AUTOSAR XML (schema 4-3-0)
package /Impl_SWC_HALOUT_ARPkg
  swc implementation Impl_SWC_HALOUT_type: programming-language=C, sw-version=1.0.0, vendor-id=0, behavior=SWC_HALOUT_type_IB
    code-descriptors:
      code SRC: artifact-descriptors=autosar-engineering-object={short-label=EngObject, category=SWSRC}
    resource consumption ResourceConsumption
      memory section MEM_SWC_HALOUT_CAL: size=0, sw-addrmethod=CAL, symbol=CAL
      memory section MEM_SWC_HALOUT_CODE: size=0, sw-addrmethod=CODE, symbol=CODE
package /SWC_HALOUT_ARPkg
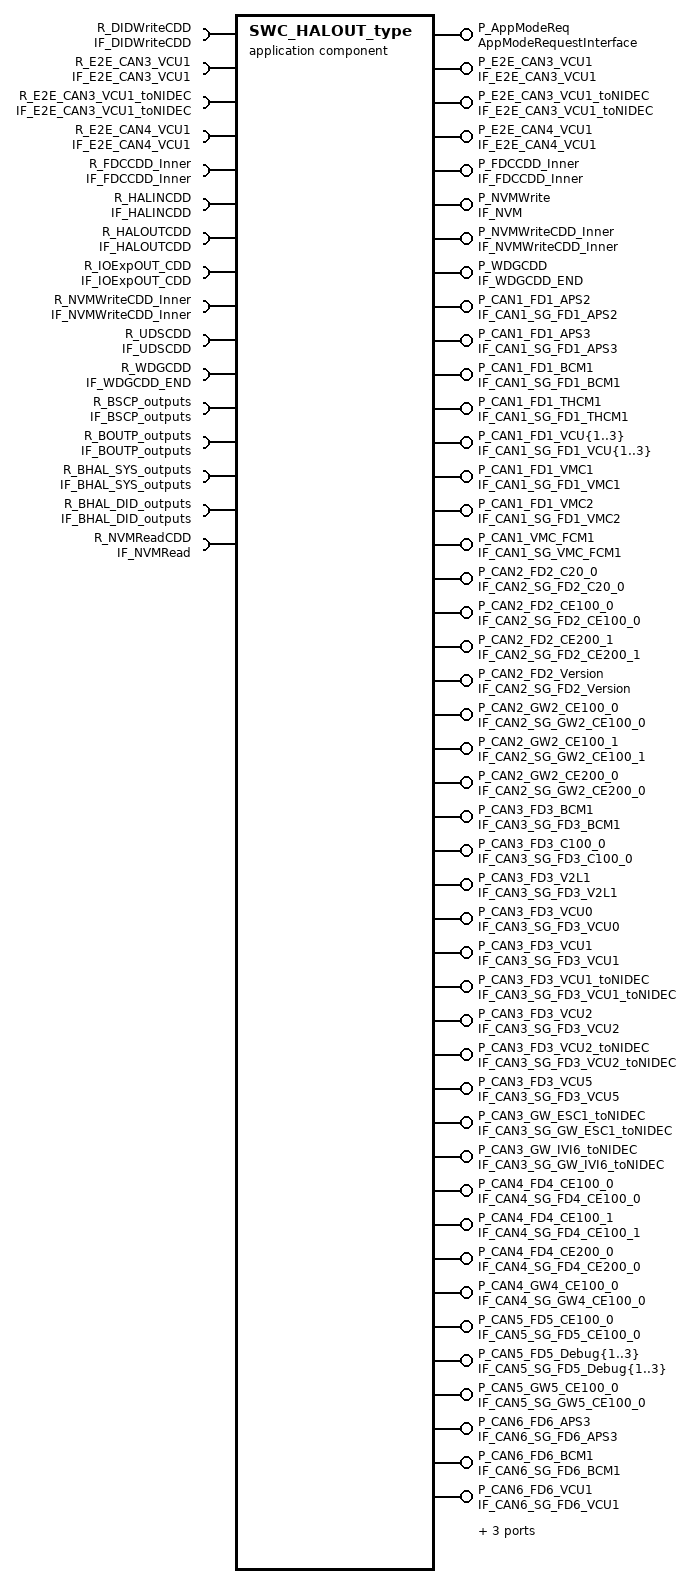
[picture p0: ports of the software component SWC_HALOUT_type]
  application sw component type SWC_HALOUT_type
    51 x provide port:
      P_AppModeReq: provided-interface=AppModeRequestInterface
      P_E2E_CAN3_VCU1: provided-interface=IF_E2E_CAN3_VCU1
      P_E2E_CAN3_VCU1_toNIDEC: provided-interface=IF_E2E_CAN3_VCU1_toNIDEC
      P_E2E_CAN4_VCU1: provided-interface=IF_E2E_CAN4_VCU1
      P_FDCCDD_Inner: provided-interface=IF_FDCCDD_Inner
      P_NVMWrite: nv-provide-com-spec{ram-block-init-value=ValueSpecification_:1024 x 0, rom-block-init-value=ValueSpecification_:1024 x 0, variable=NV_FVTDataArray}, provided-interface=IF_NVM
      P_NVMWriteCDD_Inner: provided-interface=IF_NVMWriteCDD_Inner
      P_WDGCDD: provided-interface=IF_WDGCDD_END
      P_CAN1_FD1_APS2: provided-interface=IF_CAN1_SG_FD1_APS2
      P_CAN1_FD1_APS3: provided-interface=IF_CAN1_SG_FD1_APS3
      P_CAN1_FD1_BCM1: provided-interface=IF_CAN1_SG_FD1_BCM1
      P_CAN1_FD1_THCM1: provided-interface=IF_CAN1_SG_FD1_THCM1
      P_CAN1_FD1_VCU{1..3}: provided-interface=IF_CAN1_SG_FD1_VCU{1..3}
      P_CAN1_FD1_VMC1: provided-interface=IF_CAN1_SG_FD1_VMC1
      P_CAN1_FD1_VMC2: provided-interface=IF_CAN1_SG_FD1_VMC2
      P_CAN1_VMC_FCM1: provided-interface=IF_CAN1_SG_VMC_FCM1
      P_CAN2_FD2_C20_0: provided-interface=IF_CAN2_SG_FD2_C20_0
      P_CAN2_FD2_CE100_0: provided-interface=IF_CAN2_SG_FD2_CE100_0
      P_CAN2_FD2_CE200_1: provided-interface=IF_CAN2_SG_FD2_CE200_1
      P_CAN2_FD2_Version: provided-interface=IF_CAN2_SG_FD2_Version
      P_CAN2_GW2_CE100_0: provided-interface=IF_CAN2_SG_GW2_CE100_0
      P_CAN2_GW2_CE100_1: provided-interface=IF_CAN2_SG_GW2_CE100_1
      P_CAN2_GW2_CE200_0: provided-interface=IF_CAN2_SG_GW2_CE200_0
      P_CAN3_FD3_BCM1: provided-interface=IF_CAN3_SG_FD3_BCM1
      P_CAN3_FD3_C100_0: provided-interface=IF_CAN3_SG_FD3_C100_0
      P_CAN3_FD3_V2L1: provided-interface=IF_CAN3_SG_FD3_V2L1
      P_CAN3_FD3_VCU0: provided-interface=IF_CAN3_SG_FD3_VCU0
      P_CAN3_FD3_VCU1: provided-interface=IF_CAN3_SG_FD3_VCU1
      P_CAN3_FD3_VCU1_toNIDEC: provided-interface=IF_CAN3_SG_FD3_VCU1_toNIDEC
      P_CAN3_FD3_VCU2: provided-interface=IF_CAN3_SG_FD3_VCU2
      P_CAN3_FD3_VCU2_toNIDEC: provided-interface=IF_CAN3_SG_FD3_VCU2_toNIDEC
      P_CAN3_FD3_VCU5: provided-interface=IF_CAN3_SG_FD3_VCU5
      P_CAN3_GW_ESC1_toNIDEC: provided-interface=IF_CAN3_SG_GW_ESC1_toNIDEC
      P_CAN3_GW_IVI6_toNIDEC: provided-interface=IF_CAN3_SG_GW_IVI6_toNIDEC
      P_CAN4_FD4_CE100_0: provided-interface=IF_CAN4_SG_FD4_CE100_0
      P_CAN4_FD4_CE100_1: provided-interface=IF_CAN4_SG_FD4_CE100_1
      P_CAN4_FD4_CE200_0: provided-interface=IF_CAN4_SG_FD4_CE200_0
      P_CAN4_GW4_CE100_0: provided-interface=IF_CAN4_SG_GW4_CE100_0
      P_CAN5_FD5_CE100_0: provided-interface=IF_CAN5_SG_FD5_CE100_0
      P_CAN5_FD5_Debug{1..3}: provided-interface=IF_CAN5_SG_FD5_Debug{1..3}
      P_CAN5_GW5_CE100_0: provided-interface=IF_CAN5_SG_GW5_CE100_0
      P_CAN6_FD6_APS3: provided-interface=IF_CAN6_SG_FD6_APS3
      P_CAN6_FD6_BCM1: provided-interface=IF_CAN6_SG_FD6_BCM1
      P_CAN6_FD6_VCU1: provided-interface=IF_CAN6_SG_FD6_VCU1
      P_CAN6_FD6_VCU2: provided-interface=IF_CAN6_SG_FD6_VCU2
      P_CAN6_FD6_VMC1: provided-interface=IF_CAN6_SG_FD6_VMC1
      P_CAN6_GW6_CE100_0: provided-interface=IF_CAN6_SG_GW6_CE100_0
    16 x require port:
      R_DIDWriteCDD: required-interface=IF_DIDWriteCDD
      R_E2E_CAN3_VCU1: required-interface=IF_E2E_CAN3_VCU1
      R_E2E_CAN3_VCU1_toNIDEC: required-interface=IF_E2E_CAN3_VCU1_toNIDEC
      R_E2E_CAN4_VCU1: required-interface=IF_E2E_CAN4_VCU1
      R_FDCCDD_Inner: required-interface=IF_FDCCDD_Inner
      R_HALINCDD: required-interface=IF_HALINCDD
      R_HALOUTCDD: required-interface=IF_HALOUTCDD
      R_IOExpOUT_CDD: required-interface=IF_IOExpOUT_CDD
      R_NVMWriteCDD_Inner: required-interface=IF_NVMWriteCDD_Inner
      R_UDSCDD: required-interface=IF_UDSCDD
      R_WDGCDD: required-interface=IF_WDGCDD_END
      R_BSCP_outputs: required-interface=IF_BSCP_outputs
      R_BOUTP_outputs: required-interface=IF_BOUTP_outputs
      R_BHAL_SYS_outputs: required-interface=IF_BHAL_SYS_outputs
      R_BHAL_DID_outputs: required-interface=IF_BHAL_DID_outputs
      R_NVMReadCDD: required-interface=IF_NVMRead
    behavior SWC_HALOUT_type_IB: data-type-mapping=AppModeTypeMap, handle-termination-and-restart=NO-SUPPORT
      8 x timing event:
        TE_HALOUT_100ms: start-on-event=run_SWC_HALOUT_Tx_100ms, period=0.1
        TE_HALOUT_1000ms: start-on-event=run_SWC_HALOUT_Tx_1000ms, period=1
        TE_HALOUT_20ms: start-on-event=run_SWC_HALOUT_Tx_20ms, period=0.02
        TE_HALOUT_500ms: start-on-event=run_SWC_HALOUT_Tx_500ms, period=0.5
        TE_HALOUT_5000ms: start-on-event=run_SWC_HALOUT_Tx_5000ms, period=5
        TE_HALOUT_10ms: start-on-event=run_SWC_HALOUT_Tx_10ms, period=0.01
        TE_HALOUT_5ms: start-on-event=run_SWC_HALOUT_Tx_5ms, period=0.005
        TE_UDS_10ms: start-on-event=run_SWC_HALOUT_UDS_10ms, period=0.01
      6 x operation invoked event:
        oie_P_WDGCDD_CSOP_Call_WDG_AppEnd: start-on-event=run_SWC_HALOUT_AppCallWDG_End, operation=P_WDGCDD.CSOP_Call_WDG_AppEnd
        oie_P_E2E_CAN3_VCU1_CSOP_Write_CAN3_VCU1: start-on-event=run_SWC_HALOUT_E2E_Write_CAN3VCU1, operation=P_E2E_CAN3_VCU1.CSOP_Write_CAN3_VCU1
        oie_P_E2E_CAN3_VCU1_CSOP_Write_CAN3_VCU1_toNIDEC: start-on-event=run_SWC_HALOUT_E2E_Write_CAN3VCU1_toNIDEC, operation=P_E2E_CAN3_VCU1_toNIDEC.CSOP_Write_CAN3_VCU1_toNIDEC
        oie_P_E2E_CAN4_VCU1_CSOP_Write_CAN4_VCU1: start-on-event=run_SWC_HALOUT_E2E_Write_CAN4VCU1, operation=P_E2E_CAN4_VCU1.CSOP_Write_CAN4_VCU1
        oie_P_FDCCDD_Inner_CSOP_FDC_AppCallSleep: start-on-event=run_SWC_HALOUT_AppCallSleep, operation=P_FDCCDD_Inner.CSOP_FDC_AppCallSleep
        oie_P_NVMWriteCDD_Inner_NVM_WriteOperation: start-on-event=run_SWC_HALOUT_NvmWrite, operation=P_NVMWriteCDD_Inner.NVM_WriteOperation
      explicit-inter-runnable-variables:
        25 x data:
          IRV_ms10_CAN1_SG_FD1_APS3: type=DT_CAN1_SG_FD1_APS3
          IRV_ms10_CAN1_SG_FD1_VCU2: type=DT_CAN1_SG_FD1_VCU2
          IRV_ms10_CAN1_SG_FD1_VCU3: type=DT_CAN1_SG_FD1_VCU3
          IRV_ms10_CAN1_SG_VMC_FCM1: type=DT_CAN1_SG_VMC_FCM1
          IRV_ms10_CAN3_SG_FD3_VCU0: type=DT_CAN3_SG_FD3_VCU0
          IRV_ms10_CAN3_SG_FD3_VCU2: type=DT_CAN3_SG_FD3_VCU2
          IRV_ms10_CAN3_SG_FD3_VCU2_toNIDEC: type=DT_CAN3_SG_FD3_VCU2_toNIDEC
          IRV_ms10_CAN3_SG_FD3_VCU5: type=DT_CAN3_SG_FD3_VCU5
          IRV_ms10_CAN3_SG_GW_ESC1_toNIDEC: type=DT_CAN3_SG_GW_ESC1_toNIDEC
          IRV_ms10_CAN5_SG_FD5_Debug3: type=DT_CAN5_SG_FD5_Debug3
          IRV_ms10_CAN6_SG_FD6_APS3: type=DT_CAN6_SG_FD6_APS3
          IRV_ms10_CAN6_SG_FD6_VCU2: type=DT_CAN6_SG_FD6_VCU2
          IRV_ms100_CAN1_SG_FD1_THCM1: type=DT_CAN1_SG_FD1_THCM1
          IRV_ms100_CAN2_SG_GW2_CE100_1: type=DT_CAN2_SG_GW2_CE100_1
          IRV_ms100_CAN3_SG_FD3_C100_0: type=DT_CAN3_SG_FD3_C100_0
          IRV_ms100_CAN5_SG_GW5_CE100_0: type=DT_CAN5_SG_GW5_CE100_0
          IRV_ms1000_CAN3_SG_GW_IVI6_toNIDEC: type=DT_CAN3_SG_GW_IVI6_toNIDEC
          IRV_ms20_CAN1_SG_FD1_APS2: type=DT_CAN1_SG_FD1_APS2
          IRV_ms20_CAN2_SG_FD2_C20_0: type=DT_CAN2_SG_FD2_C20_0
          IRV_ms500_CAN1_SG_FD1_VMC2: type=DT_CAN1_SG_FD1_VMC2
          IRV_ms5000_CAN2_SG_FD2_Version: type=DT_CAN2_SG_FD2_Version
          IRV_E2E_CAN3_SG_FD3_VCU1: type=DT_CAN3_SG_FD3_VCU1
          IRV_E2E_CAN3_SG_FD3_VCU1_toNIDEC: type=DT_CAN3_SG_FD3_VCU1_toNIDEC
          IRV_E2E_CAN4_SG_FD4_CE100_0: type=DT_CAN4_SG_FD4_CE100_0
          IRV_u8Array1024_NvmWriteArray: type=u8_FVTNVMArray1024_type
      port-api-options:
        enable-take-address=false, indirect-api=false, port=P_FDCCDD_Inner
        enable-take-address=false, indirect-api=false, port=P_NVMWriteCDD_Inner
        enable-take-address=false, indirect-api=false, port=P_E2E_CAN3_VCU1
        enable-take-address=false, indirect-api=false, port=P_E2E_CAN3_VCU1_toNIDEC
        enable-take-address=false, indirect-api=false, port=P_E2E_CAN4_VCU1
        enable-take-address=false, indirect-api=false, port=P_WDGCDD
      14 x runnable:
        run_SWC_HALOUT_Tx_100ms
          data-send-points:
            4 x access:
              dsp_CAN1_SG_FD1_THCM1: accessed-variable=P_CAN1_FD1_THCM1.CAN1_SG_FD1_THCM1
              dsp_CAN2_SG_GW2_CE100_1: accessed-variable=P_CAN2_GW2_CE100_1.CAN2_SG_GW2_CE100_1
              dsp_CAN3_SG_FD3_C100_0: accessed-variable=P_CAN3_FD3_C100_0.CAN3_SG_FD3_C100_0
              dsp_CAN5_SG_GW5_CE100_0: accessed-variable=P_CAN5_GW5_CE100_0.CAN5_SG_GW5_CE100_0
          read-local-variables:
            4 x access:
              IRV_ms100_CAN1_SG_FD1_THCM1: accessed-variable=IRV_ms100_CAN1_SG_FD1_THCM1
              IRV_ms100_CAN2_SG_GW2_CE100_1: accessed-variable=IRV_ms100_CAN2_SG_GW2_CE100_1
              IRV_ms100_CAN3_SG_FD3_C100_0: accessed-variable=IRV_ms100_CAN3_SG_FD3_C100_0
              IRV_ms100_CAN5_SG_GW5_CE100_0: accessed-variable=IRV_ms100_CAN5_SG_GW5_CE100_0
        run_SWC_HALOUT_Tx_1000ms
          data-send-points:
            access dsp_CAN3_SG_GW_IVI6_toNIDEC: accessed-variable=P_CAN3_GW_IVI6_toNIDEC.CAN3_SG_GW_IVI6_toNIDEC
          read-local-variables:
            access IRV_ms1000_CAN3_SG_GW_IVI6_toNIDEC: accessed-variable=IRV_ms1000_CAN3_SG_GW_IVI6_toNIDEC
        run_SWC_HALOUT_Tx_20ms
          data-send-points:
            access dsp_CAN1_SG_FD1_APS2: accessed-variable=P_CAN1_FD1_APS2.CAN1_SG_FD1_APS2
            access dsp_CAN2_SG_FD2_C20_0: accessed-variable=P_CAN2_FD2_C20_0.CAN2_SG_FD2_C20_0
          read-local-variables:
            access IRV_ms20_CAN1_SG_FD1_APS2: accessed-variable=IRV_ms20_CAN1_SG_FD1_APS2
            access IRV_ms20_CAN2_SG_FD2_C20_0: accessed-variable=IRV_ms20_CAN2_SG_FD2_C20_0
        run_SWC_HALOUT_Tx_500ms
          data-send-points:
            access dsp_CAN1_SG_FD1_VMC2: accessed-variable=P_CAN1_FD1_VMC2.CAN1_SG_FD1_VMC2
          read-local-variables:
            access IRV_ms500_CAN1_SG_FD1_VMC2: accessed-variable=IRV_ms500_CAN1_SG_FD1_VMC2
        run_SWC_HALOUT_Tx_5000ms
          data-send-points:
            access dsp_CAN2_SG_FD2_Version: accessed-variable=P_CAN2_FD2_Version.CAN2_SG_FD2_Version
          read-local-variables:
            access IRV_ms5000_CAN2_SG_FD2_Version: accessed-variable=IRV_ms5000_CAN2_SG_FD2_Version
        run_SWC_HALOUT_AppCallSleep
          data-send-points:
            access dsp_requestedMode: accessed-variable=P_AppModeReq.requestedMode
        run_SWC_HALOUT_E2E_Write_CAN3VCU1
          data-send-points:
            access dsp_CAN3_SG_FD3_VCU1: accessed-variable=P_CAN3_FD3_VCU1.CAN3_SG_FD3_VCU1
          read-local-variables:
            access IRV_E2E_CAN3_SG_FD3_VCU1: accessed-variable=IRV_E2E_CAN3_SG_FD3_VCU1
        run_SWC_HALOUT_E2E_Write_CAN3VCU1_toNIDEC
          data-send-points:
            access dsp_CAN3_SG_FD3_VCU1_toNIDEC: accessed-variable=P_CAN3_FD3_VCU1_toNIDEC.CAN3_SG_FD3_VCU1_toNIDEC
          read-local-variables:
            access IRV_E2E_CAN3_SG_FD3_VCU1_toNIDEC: accessed-variable=IRV_E2E_CAN3_SG_FD3_VCU1_toNIDEC
        run_SWC_HALOUT_E2E_Write_CAN4VCU1
          data-send-points:
            access dsp_CAN4_SG_FD4_CE100_0: accessed-variable=P_CAN4_FD4_CE100_0.CAN4_SG_FD4_CE100_0
          read-local-variables:
            access IRV_E2E_CAN4_SG_FD4_CE100_0: accessed-variable=IRV_E2E_CAN4_SG_FD4_CE100_0
        run_SWC_HALOUT_NvmWrite
          data-send-points:
            access dsp_NV_FVTDataArray: accessed-variable=P_NVMWrite.NV_FVTDataArray
          read-local-variables:
            access IRV_u8Array1024_NvmWriteArray: accessed-variable=IRV_u8Array1024_NvmWriteArray
        run_SWC_HALOUT_Tx_5ms
          data-receive-point-by-arguments:
            5 x access:
              drparg_BSCP_outputs: accessed-variable=R_BSCP_outputs.BSCP_outputs
              drparg_BOUTP_outputs: accessed-variable=R_BOUTP_outputs.BOUTP_outputs
              drparg_BHAL_SYS_outputs: accessed-variable=R_BHAL_SYS_outputs.BHAL_SYS_outputs
              drparg_BHAL_DID_outputs: accessed-variable=R_BHAL_DID_outputs.BHAL_DID_outputs
              drparg_u8Array1024_NVMReadData: accessed-variable=R_NVMReadCDD.u8Array1024_NVMReadData
          data-send-points:
            19 x access:
              dsp_CAN1_SG_FD1_BCM1: accessed-variable=P_CAN1_FD1_BCM1.CAN1_SG_FD1_BCM1
              dsp_CAN1_SG_FD1_VCU1: accessed-variable=P_CAN1_FD1_VCU1.CAN1_SG_FD1_VCU1
              dsp_CAN1_SG_FD1_VMC1: accessed-variable=P_CAN1_FD1_VMC1.CAN1_SG_FD1_VMC1
              dsp_CAN2_SG_FD2_CE100_0: accessed-variable=P_CAN2_FD2_CE100_0.CAN2_SG_FD2_CE100_0
              dsp_CAN2_SG_FD2_CE200_1: accessed-variable=P_CAN2_FD2_CE200_1.CAN2_SG_FD2_CE200_1
              dsp_CAN2_SG_GW2_CE100_0: accessed-variable=P_CAN2_GW2_CE100_0.CAN2_SG_GW2_CE100_0
              dsp_CAN2_SG_GW2_CE200_0: accessed-variable=P_CAN2_GW2_CE200_0.CAN2_SG_GW2_CE200_0
              dsp_CAN3_SG_FD3_BCM1: accessed-variable=P_CAN3_FD3_BCM1.CAN3_SG_FD3_BCM1
              dsp_CAN3_SG_FD3_V2L1: accessed-variable=P_CAN3_FD3_V2L1.CAN3_SG_FD3_V2L1
              dsp_CAN4_SG_FD4_CE100_1: accessed-variable=P_CAN4_FD4_CE100_1.CAN4_SG_FD4_CE100_1
              dsp_CAN4_SG_FD4_CE200_0: accessed-variable=P_CAN4_FD4_CE200_0.CAN4_SG_FD4_CE200_0
              dsp_CAN4_SG_GW4_CE100_0: accessed-variable=P_CAN4_GW4_CE100_0.CAN4_SG_GW4_CE100_0
              dsp_CAN5_SG_FD5_CE100_0: accessed-variable=P_CAN5_FD5_CE100_0.CAN5_SG_FD5_CE100_0
              dsp_CAN5_SG_FD5_Debug1: accessed-variable=P_CAN5_FD5_Debug1.CAN5_SG_FD5_Debug1
              dsp_CAN5_SG_FD5_Debug2: accessed-variable=P_CAN5_FD5_Debug2.CAN5_SG_FD5_Debug2
              dsp_CAN6_SG_FD6_BCM1: accessed-variable=P_CAN6_FD6_BCM1.CAN6_SG_FD6_BCM1
              dsp_CAN6_SG_FD6_VCU1: accessed-variable=P_CAN6_FD6_VCU1.CAN6_SG_FD6_VCU1
              dsp_CAN6_SG_FD6_VMC1: accessed-variable=P_CAN6_FD6_VMC1.CAN6_SG_FD6_VMC1
              dsp_CAN6_SG_GW6_CE100_0: accessed-variable=P_CAN6_GW6_CE100_0.CAN6_SG_GW6_CE100_0
          72 x sync call, all with timeout=0.0:
            scp_CSOP_DdmRestartOperation: operation=R_UDSCDD.CSOP_DdmRestartOperationCycle
            scp_CSOP_FDC_AppCallSleep: operation=R_FDCCDD_Inner.CSOP_FDC_AppCallSleep
            scp_CSOP_IOExpSetVal: operation=R_IOExpOUT_CDD.CSOP_IOExpSetVal
            scp_CSOP_SetAcoreRebootCmdACK: operation=R_HALOUTCDD.CSOP_SetAcoreRebootCmdACK
            scp_CSOP_SetDTCStatus: operation=R_UDSCDD.CSOP_SetDTCStatus
            scp_CSOP_SetHazardIND: operation=R_HALOUTCDD.CSOP_SetHazardIND
            scp_CSOP_SetSysPwrStat: operation=R_HALOUTCDD.CSOP_SetSysPwrStat
            scp_CSOP_AppNmStateReq: operation=R_HALOUTCDD.CSOP_AppNmStateReq
            scp_CSOP_Call_WDG_AppEnd: operation=R_WDGCDD.CSOP_Call_WDG_AppEnd
            scp_CSOP_SleepRequest: operation=R_HALOUTCDD.CSOP_SleepRequest
            scp_CSOP_TPMSSensorIDRegSetResults: operation=R_HALOUTCDD.CSOP_TPMSSensorIDRegSetResults
            scp_CSOP_ResetPedalZeroPosDone: operation=R_HALOUTCDD.CSOP_ResetPedalZeroPosDone
            scp_CSOP_Write_CAN3_VCU1: operation=R_E2E_CAN3_VCU1.CSOP_Write_CAN3_VCU1
            scp_CSOP_Write_CAN3_VCU1_toNIDEC: operation=R_E2E_CAN3_VCU1_toNIDEC.CSOP_Write_CAN3_VCU1_toNIDEC
            scp_CSOP_Write_CAN4_VCU1: operation=R_E2E_CAN4_VCU1.CSOP_Write_CAN4_VCU1
            scp_CSOP_DIDSet_XWDMode: operation=R_DIDWriteCDD.CSOP_DIDSet_XWDMode
            scp_CSOP_DIDSet_DKCKey: operation=R_DIDWriteCDD.CSOP_DIDSet_DKCKey
            scp_CSOP_DIDSet_DynoMode: operation=R_DIDWriteCDD.CSOP_DIDSet_DynoMode
            scp_CSOP_DIDSet_APPPedalZP: operation=R_DIDWriteCDD.CSOP_DIDSet_APPPedalZP
            scp_CSOP_DIDSet_NVMPedalZP: operation=R_DIDWriteCDD.CSOP_DIDSet_NVMPedalZP
            scp_CSOP_DIDSet_TurnLampFRThreCurr: operation=R_DIDWriteCDD.CSOP_DIDSet_TurnLampFRThreCurr
            scp_CSOP_DIDSet_TurnLampRRThreCurr: operation=R_DIDWriteCDD.CSOP_DIDSet_TurnLampRRThreCurr
            scp_CSOP_DIDSet_TurnLampFLThreCurr: operation=R_DIDWriteCDD.CSOP_DIDSet_TurnLampFLThreCurr
            scp_CSOP_DIDSet_TurnLampRLThreCurr: operation=R_DIDWriteCDD.CSOP_DIDSet_TurnLampRLThreCurr
            scp_CSOP_DIDSet_FMHTimer: operation=R_DIDWriteCDD.CSOP_DIDSet_FMHTimer
            scp_CSOP_DIDSet_AutoLock: operation=R_DIDWriteCDD.CSOP_DIDSet_AutoLock
            scp_CSOP_DIDSet_DRLDis: operation=R_DIDWriteCDD.CSOP_DIDSet_DRLDis
            scp_CSOP_DIDSet_AutoWipHSpdEN: operation=R_DIDWriteCDD.CSOP_DIDSet_AutoWipHSpdEN
            scp_CSOP_DIDSet_WipRLSCmdHoldFilter: operation=R_DIDWriteCDD.CSOP_DIDSet_WipRLSCmdHoldFilter
            scp_CSOP_DIDSet_WipRLSCmdCutFilter: operation=R_DIDWriteCDD.CSOP_DIDSet_WipRLSCmdCutFilter
            scp_CSOP_DIDSet_LFSensorID: operation=R_DIDWriteCDD.CSOP_DIDSet_LFSensorID
            scp_CSOP_DIDSet_RFSensorID: operation=R_DIDWriteCDD.CSOP_DIDSet_RFSensorID
            scp_CSOP_DIDSet_LRSensorID: operation=R_DIDWriteCDD.CSOP_DIDSet_LRSensorID
            scp_CSOP_DIDSet_RRSensorID: operation=R_DIDWriteCDD.CSOP_DIDSet_RRSensorID
            scp_CSOP_DIDSet_WhlPres: operation=R_DIDWriteCDD.CSOP_DIDSet_WhlPres
            scp_CSOP_DIDSet_WhlTmp: operation=R_DIDWriteCDD.CSOP_DIDSet_WhlTmp
            scp_CSOP_DIDSet_WhlSensorBattSta: operation=R_DIDWriteCDD.CSOP_DIDSet_WhlSensorBattSta
            scp_CSOP_DIDSet_LFLowPresThre: operation=R_DIDWriteCDD.CSOP_DIDSet_LFLowPresThre
            scp_CSOP_DIDSet_RFLowPresThre: operation=R_DIDWriteCDD.CSOP_DIDSet_RFLowPresThre
            scp_CSOP_DIDSet_LRLowPresThre: operation=R_DIDWriteCDD.CSOP_DIDSet_LRLowPresThre
            scp_CSOP_DIDSet_RRLowPresThre: operation=R_DIDWriteCDD.CSOP_DIDSet_RRLowPresThre
            scp_CSOP_DIDSet_SensorMode: operation=R_DIDWriteCDD.CSOP_DIDSet_SensorMode
            scp_CSOP_DIDSet_TPMSLearnSta: operation=R_DIDWriteCDD.CSOP_DIDSet_TPMSLearnSta
            scp_CSOP_DIDSet_USSConfig: operation=R_DIDWriteCDD.CSOP_DIDSet_USSConfig
            scp_CSOP_DIDSet_TireSize: operation=R_DIDWriteCDD.CSOP_DIDSet_TireSize
            scp_CSOP_DIDSet_APSFunConfig: operation=R_DIDWriteCDD.CSOP_DIDSet_APSFunConfig
            scp_CSOP_DIDSet_VSS: operation=R_DIDWriteCDD.CSOP_DIDSet_VSS
            scp_CSOP_DIDSet_OBDReq: operation=R_DIDWriteCDD.CSOP_DIDSet_OBDReq
            scp_CSOP_DIDSet_RUNTM: operation=R_DIDWriteCDD.CSOP_DIDSet_RUNTM
            scp_CSOP_DIDSet_MILDIST: operation=R_DIDWriteCDD.CSOP_DIDSet_MILDIST
            scp_CSOP_DIDSet_CLRDIST: operation=R_DIDWriteCDD.CSOP_DIDSet_CLRDIST
            scp_CSOP_DIDSet_APPD: operation=R_DIDWriteCDD.CSOP_DIDSet_APPD
            scp_CSOP_DIDSet_APPE: operation=R_DIDWriteCDD.CSOP_DIDSet_APPE
            scp_CSOP_DIDSet_ODOMETER: operation=R_DIDWriteCDD.CSOP_DIDSet_ODOMETER
            scp_CSOP_DIDSet_NUMPSATRIPSFLTMEMCLR: operation=R_DIDWriteCDD.CSOP_DIDSet_NUMPSATRIPSFLTMEMCLR
            scp_CSOP_DIDSet_VIN: operation=R_DIDWriteCDD.CSOP_DIDSet_VIN
            scp_CSOP_DIDSet_CALID: operation=R_DIDWriteCDD.CSOP_DIDSet_CALID
            scp_CSOP_DIDSet_ECUNAME: operation=R_DIDWriteCDD.CSOP_DIDSet_ECUNAME
            scp_CSOP_DIDSet_ProtocolId: operation=R_DIDWriteCDD.CSOP_DIDSet_ProtocolId
            scp_CSOP_DIDSet_TestGroup: operation=R_DIDWriteCDD.CSOP_DIDSet_TestGroup
            scp_CSOP_DIDSet_PSA: operation=R_DIDWriteCDD.CSOP_DIDSet_PSA
            scp_CSOP_DIDSet_PKE: operation=R_DIDWriteCDD.CSOP_DIDSet_PKE
            scp_CSOP_DIDSet_CDEODT: operation=R_DIDWriteCDD.CSOP_DIDSet_CDEODT
            scp_CSOP_DIDSet_QTYPSATRIPS: operation=R_DIDWriteCDD.CSOP_DIDSet_QTYPSATRIPS
            scp_CSOP_DIDSet_DKCSta: operation=R_DIDWriteCDD.CSOP_DIDSet_DKCSta
            scp_CSOP_DIDSet_DKCBLESta: operation=R_DIDWriteCDD.CSOP_DIDSet_DKCBLESta
            scp_CSOP_DIDSet_UWBAnchorSta: operation=R_DIDWriteCDD.CSOP_DIDSet_UWBAnchorSta
            scp_CSOP_DIDSet_LIDAAnchorSta: operation=R_DIDWriteCDD.CSOP_DIDSet_LIDAAnchorSta
            scp_CSOP_DIDSet_DoorNFCAnchorSta: operation=R_DIDWriteCDD.CSOP_DIDSet_DoorNFCAnchorSta
            scp_CSOP_DIDSet_UIDSta: operation=R_DIDWriteCDD.CSOP_DIDSet_UIDSta
            scp_CSOP_DIDSet_FDDKCCoordXY: operation=R_DIDWriteCDD.CSOP_DIDSet_FDDKCCoordXY
            scp_NVM_WriteOperation: operation=R_NVMWriteCDD_Inner.NVM_WriteOperation
          written-local-variables:
            25 x access:
              IRV_ms10_CAN1_SG_FD1_APS3: accessed-variable=IRV_ms10_CAN1_SG_FD1_APS3
              IRV_ms10_CAN1_SG_FD1_VCU2: accessed-variable=IRV_ms10_CAN1_SG_FD1_VCU2
              IRV_ms10_CAN1_SG_FD1_VCU3: accessed-variable=IRV_ms10_CAN1_SG_FD1_VCU3
              IRV_ms10_CAN1_SG_VMC_FCM1: accessed-variable=IRV_ms10_CAN1_SG_VMC_FCM1
              IRV_ms10_CAN3_SG_FD3_VCU0: accessed-variable=IRV_ms10_CAN3_SG_FD3_VCU0
              IRV_ms10_CAN3_SG_FD3_VCU2: accessed-variable=IRV_ms10_CAN3_SG_FD3_VCU2
              IRV_ms10_CAN3_SG_FD3_VCU2_toNIDEC: accessed-variable=IRV_ms10_CAN3_SG_FD3_VCU2_toNIDEC
              IRV_ms10_CAN3_SG_FD3_VCU5: accessed-variable=IRV_ms10_CAN3_SG_FD3_VCU5
              IRV_ms10_CAN3_SG_GW_ESC1_toNIDEC: accessed-variable=IRV_ms10_CAN3_SG_GW_ESC1_toNIDEC
              IRV_ms10_CAN5_SG_FD5_Debug3: accessed-variable=IRV_ms10_CAN5_SG_FD5_Debug3
              IRV_ms10_CAN6_SG_FD6_APS3: accessed-variable=IRV_ms10_CAN6_SG_FD6_APS3
              IRV_ms10_CAN6_SG_FD6_VCU2: accessed-variable=IRV_ms10_CAN6_SG_FD6_VCU2
              IRV_ms100_CAN1_SG_FD1_THCM1: accessed-variable=IRV_ms100_CAN1_SG_FD1_THCM1
              IRV_ms100_CAN2_SG_GW2_CE100_1: accessed-variable=IRV_ms100_CAN2_SG_GW2_CE100_1
              IRV_ms100_CAN3_SG_FD3_C100_0: accessed-variable=IRV_ms100_CAN3_SG_FD3_C100_0
              IRV_ms100_CAN5_SG_GW5_CE100_0: accessed-variable=IRV_ms100_CAN5_SG_GW5_CE100_0
              IRV_ms1000_CAN3_SG_GW_IVI6_toNIDEC: accessed-variable=IRV_ms1000_CAN3_SG_GW_IVI6_toNIDEC
              IRV_ms20_CAN1_SG_FD1_APS2: accessed-variable=IRV_ms20_CAN1_SG_FD1_APS2
              IRV_ms20_CAN2_SG_FD2_C20_0: accessed-variable=IRV_ms20_CAN2_SG_FD2_C20_0
              IRV_ms500_CAN1_SG_FD1_VMC2: accessed-variable=IRV_ms500_CAN1_SG_FD1_VMC2
              IRV_ms5000_CAN2_SG_FD2_Version: accessed-variable=IRV_ms5000_CAN2_SG_FD2_Version
              IRV_E2E_CAN3_SG_FD3_VCU1: accessed-variable=IRV_E2E_CAN3_SG_FD3_VCU1
              IRV_E2E_CAN3_SG_FD3_VCU1_toNIDEC: accessed-variable=IRV_E2E_CAN3_SG_FD3_VCU1_toNIDEC
              IRV_E2E_CAN4_SG_FD4_CE100_0: accessed-variable=IRV_E2E_CAN4_SG_FD4_CE100_0
              IRV_u8Array1024_NvmWriteArray: accessed-variable=IRV_u8Array1024_NvmWriteArray
        run_SWC_HALOUT_Tx_10ms
          data-send-points:
            12 x access:
              dsp_CAN1_SG_FD1_APS3: accessed-variable=P_CAN1_FD1_APS3.CAN1_SG_FD1_APS3
              dsp_CAN1_SG_FD1_VCU2: accessed-variable=P_CAN1_FD1_VCU2.CAN1_SG_FD1_VCU2
              dsp_CAN1_SG_FD1_VCU3: accessed-variable=P_CAN1_FD1_VCU3.CAN1_SG_FD1_VCU3
              dsp_CAN1_SG_VMC_FCM1: accessed-variable=P_CAN1_VMC_FCM1.CAN1_SG_VMC_FCM1
              dsp_CAN3_SG_FD3_VCU0: accessed-variable=P_CAN3_FD3_VCU0.CAN3_SG_FD3_VCU0
              dsp_CAN3_SG_FD3_VCU2: accessed-variable=P_CAN3_FD3_VCU2.CAN3_SG_FD3_VCU2
              dsp_CAN3_SG_FD3_VCU2_toNIDEC: accessed-variable=P_CAN3_FD3_VCU2_toNIDEC.CAN3_SG_FD3_VCU2_toNIDEC
              dsp_CAN3_SG_FD3_VCU5: accessed-variable=P_CAN3_FD3_VCU5.CAN3_SG_FD3_VCU5
              dsp_CAN3_SG_GW_ESC1_toNIDEC: accessed-variable=P_CAN3_GW_ESC1_toNIDEC.CAN3_SG_GW_ESC1_toNIDEC
              dsp_CAN5_SG_FD5_Debug3: accessed-variable=P_CAN5_FD5_Debug3.CAN5_SG_FD5_Debug3
              dsp_CAN6_SG_FD6_APS3: accessed-variable=P_CAN6_FD6_APS3.CAN6_SG_FD6_APS3
              dsp_CAN6_SG_FD6_VCU2: accessed-variable=P_CAN6_FD6_VCU2.CAN6_SG_FD6_VCU2
          read-local-variables:
            12 x access:
              IRV_ms10_CAN1_SG_FD1_APS3: accessed-variable=IRV_ms10_CAN1_SG_FD1_APS3
              IRV_ms10_CAN1_SG_FD1_VCU2: accessed-variable=IRV_ms10_CAN1_SG_FD1_VCU2
              IRV_ms10_CAN1_SG_FD1_VCU3: accessed-variable=IRV_ms10_CAN1_SG_FD1_VCU3
              IRV_ms10_CAN1_SG_VMC_FCM1: accessed-variable=IRV_ms10_CAN1_SG_VMC_FCM1
              IRV_ms10_CAN3_SG_FD3_VCU0: accessed-variable=IRV_ms10_CAN3_SG_FD3_VCU0
              IRV_ms10_CAN3_SG_FD3_VCU2: accessed-variable=IRV_ms10_CAN3_SG_FD3_VCU2
              IRV_ms10_CAN3_SG_FD3_VCU2_toNIDEC: accessed-variable=IRV_ms10_CAN3_SG_FD3_VCU2_toNIDEC
              IRV_ms10_CAN3_SG_FD3_VCU5: accessed-variable=IRV_ms10_CAN3_SG_FD3_VCU5
              IRV_ms10_CAN3_SG_GW_ESC1_toNIDEC: accessed-variable=IRV_ms10_CAN3_SG_GW_ESC1_toNIDEC
              IRV_ms10_CAN5_SG_FD5_Debug3: accessed-variable=IRV_ms10_CAN5_SG_FD5_Debug3
              IRV_ms10_CAN6_SG_FD6_APS3: accessed-variable=IRV_ms10_CAN6_SG_FD6_APS3
              IRV_ms10_CAN6_SG_FD6_VCU2: accessed-variable=IRV_ms10_CAN6_SG_FD6_VCU2
        run_SWC_HALOUT_UDS_10ms
          sync call scp_CSOP_UDS_Main: operation=R_HALINCDD.CSOP_UDS_Main, timeout=0.0
        run_SWC_HALOUT_AppCallWDG_End
